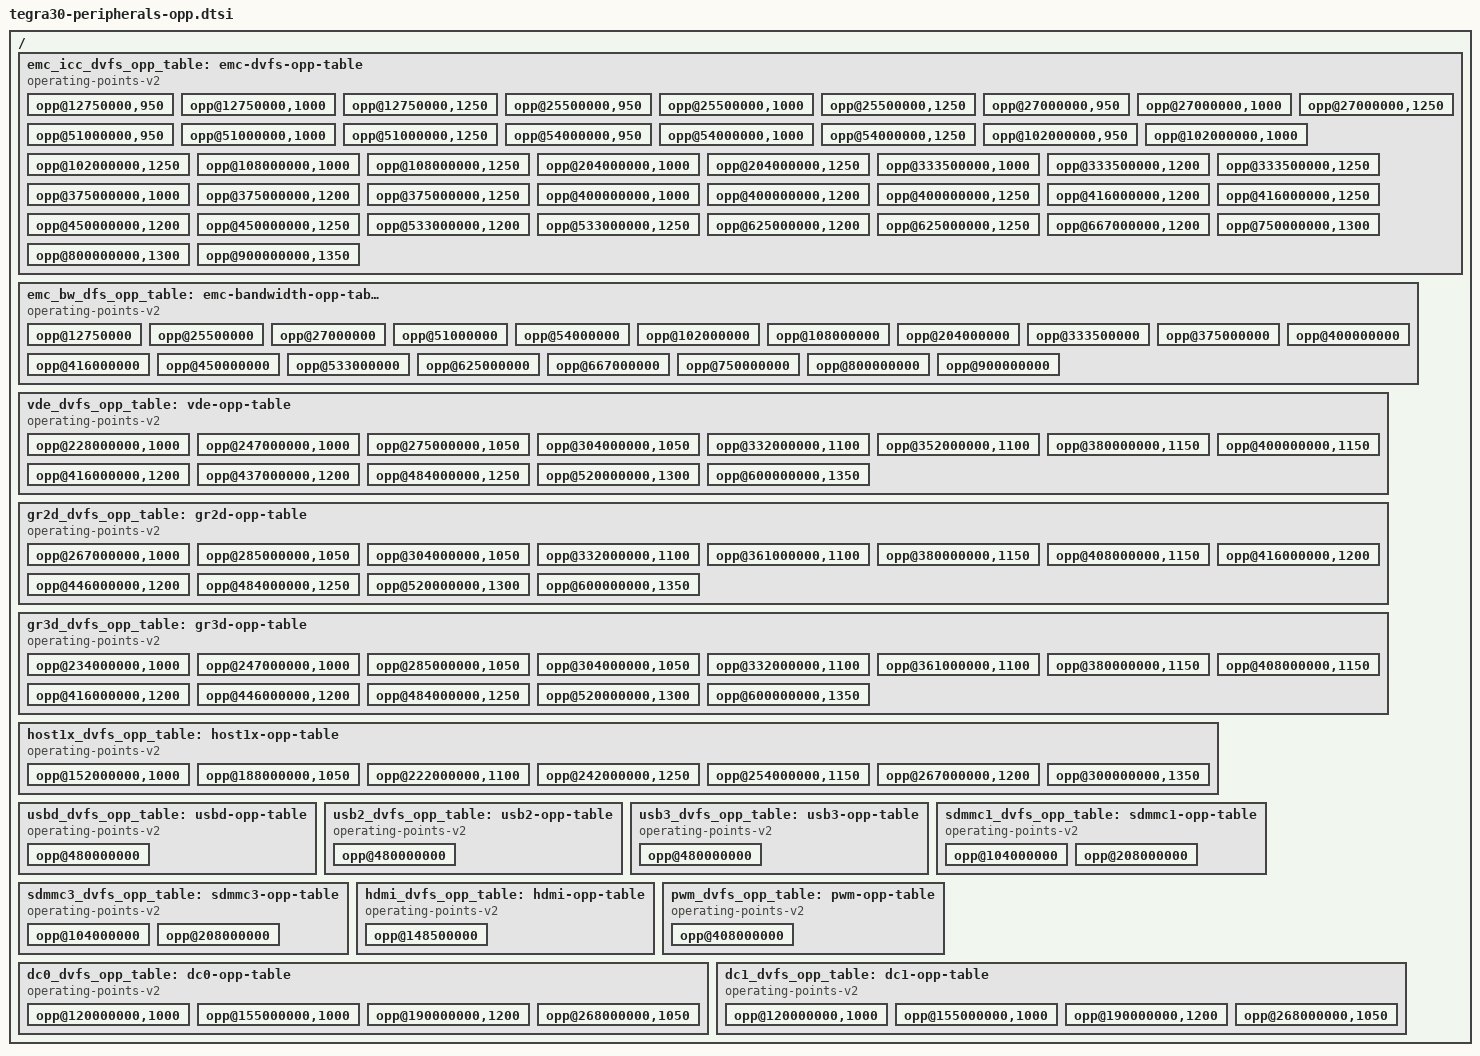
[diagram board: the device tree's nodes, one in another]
// SPDX-License-Identifier: GPL-2.0

/ {
	emc_icc_dvfs_opp_table: emc-dvfs-opp-table {
		compatible = "operating-points-v2";

		opp@12750000,950 {
			opp-microvolt = <950000 950000 1350000>;
			opp-hz = /bits/ 64 <12750000>;
			opp-supported-hw = <0x0006>;
		};

		opp@12750000,1000 {
			opp-microvolt = <1000000 1000000 1350000>;
			opp-hz = /bits/ 64 <12750000>;
			opp-supported-hw = <0x0001>;
		};

		opp@12750000,1250 {
			opp-microvolt = <1250000 1250000 1350000>;
			opp-hz = /bits/ 64 <12750000>;
			opp-supported-hw = <0x0008>;
		};

		opp@25500000,950 {
			opp-microvolt = <950000 950000 1350000>;
			opp-hz = /bits/ 64 <25500000>;
			opp-supported-hw = <0x0006>;
		};

		opp@25500000,1000 {
			opp-microvolt = <1000000 1000000 1350000>;
			opp-hz = /bits/ 64 <25500000>;
			opp-supported-hw = <0x0001>;
		};

		opp@25500000,1250 {
			opp-microvolt = <1250000 1250000 1350000>;
			opp-hz = /bits/ 64 <25500000>;
			opp-supported-hw = <0x0008>;
		};

		opp@27000000,950 {
			opp-microvolt = <950000 950000 1350000>;
			opp-hz = /bits/ 64 <27000000>;
			opp-supported-hw = <0x0006>;
		};

		opp@27000000,1000 {
			opp-microvolt = <1000000 1000000 1350000>;
			opp-hz = /bits/ 64 <27000000>;
			opp-supported-hw = <0x0001>;
		};

		opp@27000000,1250 {
			opp-microvolt = <1250000 1250000 1350000>;
			opp-hz = /bits/ 64 <27000000>;
			opp-supported-hw = <0x0008>;
		};

		opp@51000000,950 {
			opp-microvolt = <950000 950000 1350000>;
			opp-hz = /bits/ 64 <51000000>;
			opp-supported-hw = <0x0006>;
		};

		opp@51000000,1000 {
			opp-microvolt = <1000000 1000000 1350000>;
			opp-hz = /bits/ 64 <51000000>;
			opp-supported-hw = <0x0001>;
		};

		opp@51000000,1250 {
			opp-microvolt = <1250000 1250000 1350000>;
			opp-hz = /bits/ 64 <51000000>;
			opp-supported-hw = <0x0008>;
		};

		opp@54000000,950 {
			opp-microvolt = <950000 950000 1350000>;
			opp-hz = /bits/ 64 <54000000>;
			opp-supported-hw = <0x0006>;
		};

		opp@54000000,1000 {
			opp-microvolt = <1000000 1000000 1350000>;
			opp-hz = /bits/ 64 <54000000>;
			opp-supported-hw = <0x0001>;
		};

		opp@54000000,1250 {
			opp-microvolt = <1250000 1250000 1350000>;
			opp-hz = /bits/ 64 <54000000>;
			opp-supported-hw = <0x0008>;
		};

		opp@102000000,950 {
			opp-microvolt = <950000 950000 1350000>;
			opp-hz = /bits/ 64 <102000000>;
			opp-supported-hw = <0x0006>;
		};

		opp@102000000,1000 {
			opp-microvolt = <1000000 1000000 1350000>;
			opp-hz = /bits/ 64 <102000000>;
			opp-supported-hw = <0x0001>;
		};

		opp@102000000,1250 {
			opp-microvolt = <1250000 1250000 1350000>;
			opp-hz = /bits/ 64 <102000000>;
			opp-supported-hw = <0x0008>;
		};

		opp@108000000,1000 {
			opp-microvolt = <1000000 1000000 1350000>;
			opp-hz = /bits/ 64 <108000000>;
			opp-supported-hw = <0x0007>;
		};

		opp@108000000,1250 {
			opp-microvolt = <1250000 1250000 1350000>;
			opp-hz = /bits/ 64 <108000000>;
			opp-supported-hw = <0x0008>;
		};

		opp@204000000,1000 {
			opp-microvolt = <1000000 1000000 1350000>;
			opp-hz = /bits/ 64 <204000000>;
			opp-supported-hw = <0x0007>;
		};

		opp@204000000,1250 {
			opp-microvolt = <1250000 1250000 1350000>;
			opp-hz = /bits/ 64 <204000000>;
			opp-supported-hw = <0x0008>;
		};

		opp@333500000,1000 {
			opp-microvolt = <1000000 1000000 1350000>;
			opp-hz = /bits/ 64 <333500000>;
			opp-supported-hw = <0x0006>;
		};

		opp@333500000,1200 {
			opp-microvolt = <1200000 1200000 1350000>;
			opp-hz = /bits/ 64 <333500000>;
			opp-supported-hw = <0x0001>;
		};

		opp@333500000,1250 {
			opp-microvolt = <1250000 1250000 1350000>;
			opp-hz = /bits/ 64 <333500000>;
			opp-supported-hw = <0x0008>;
		};

		opp@375000000,1000 {
			opp-microvolt = <1000000 1000000 1350000>;
			opp-hz = /bits/ 64 <375000000>;
			opp-supported-hw = <0x0006>;
		};

		opp@375000000,1200 {
			opp-microvolt = <1200000 1200000 1350000>;
			opp-hz = /bits/ 64 <375000000>;
			opp-supported-hw = <0x0001>;
		};

		opp@375000000,1250 {
			opp-microvolt = <1250000 1250000 1350000>;
			opp-hz = /bits/ 64 <375000000>;
			opp-supported-hw = <0x0008>;
		};

		opp@400000000,1000 {
			opp-microvolt = <1000000 1000000 1350000>;
			opp-hz = /bits/ 64 <400000000>;
			opp-supported-hw = <0x0006>;
		};

		opp@400000000,1200 {
			opp-microvolt = <1200000 1200000 1350000>;
			opp-hz = /bits/ 64 <400000000>;
			opp-supported-hw = <0x0001>;
		};

		opp@400000000,1250 {
			opp-microvolt = <1250000 1250000 1350000>;
			opp-hz = /bits/ 64 <400000000>;
			opp-supported-hw = <0x0008>;
		};

		opp@416000000,1200 {
			opp-microvolt = <1200000 1200000 1350000>;
			opp-hz = /bits/ 64 <416000000>;
			opp-supported-hw = <0x0007>;
		};

		opp@416000000,1250 {
			opp-microvolt = <1250000 1250000 1350000>;
			opp-hz = /bits/ 64 <416000000>;
			opp-supported-hw = <0x0008>;
		};

		opp@450000000,1200 {
			opp-microvolt = <1200000 1200000 1350000>;
			opp-hz = /bits/ 64 <450000000>;
			opp-supported-hw = <0x0007>;
		};

		opp@450000000,1250 {
			opp-microvolt = <1250000 1250000 1350000>;
			opp-hz = /bits/ 64 <450000000>;
			opp-supported-hw = <0x0008>;
		};

		opp@533000000,1200 {
			opp-microvolt = <1200000 1200000 1350000>;
			opp-hz = /bits/ 64 <533000000>;
			opp-supported-hw = <0x0007>;
		};

		opp@533000000,1250 {
			opp-microvolt = <1250000 1250000 1350000>;
			opp-hz = /bits/ 64 <533000000>;
			opp-supported-hw = <0x0008>;
		};

		opp@625000000,1200 {
			opp-microvolt = <1200000 1200000 1350000>;
			opp-hz = /bits/ 64 <625000000>;
			opp-supported-hw = <0x0006>;
		};

		opp@625000000,1250 {
			opp-microvolt = <1250000 1250000 1350000>;
			opp-hz = /bits/ 64 <625000000>;
			opp-supported-hw = <0x0008>;
		};

		opp@667000000,1200 {
			opp-microvolt = <1200000 1200000 1350000>;
			opp-hz = /bits/ 64 <667000000>;
			opp-supported-hw = <0x0006>;
		};

		opp@750000000,1300 {
			opp-microvolt = <1300000 1300000 1350000>;
			opp-hz = /bits/ 64 <750000000>;
			opp-supported-hw = <0x0004>;
		};

		opp@800000000,1300 {
			opp-microvolt = <1300000 1300000 1350000>;
			opp-hz = /bits/ 64 <800000000>;
			opp-supported-hw = <0x0004>;
		};

		opp@900000000,1350 {
			opp-microvolt = <1350000 1350000 1350000>;
			opp-hz = /bits/ 64 <900000000>;
			opp-supported-hw = <0x0004>;
		};
	};

	emc_bw_dfs_opp_table: emc-bandwidth-opp-table {
		compatible = "operating-points-v2";

		opp@12750000 {
			opp-hz = /bits/ 64 <12750000>;
			opp-supported-hw = <0x000F>;
			opp-peak-kBps = <102000>;
		};

		opp@25500000 {
			opp-hz = /bits/ 64 <25500000>;
			opp-supported-hw = <0x000F>;
			opp-peak-kBps = <204000>;
		};

		opp@27000000 {
			opp-hz = /bits/ 64 <27000000>;
			opp-supported-hw = <0x000F>;
			opp-peak-kBps = <216000>;
		};

		opp@51000000 {
			opp-hz = /bits/ 64 <51000000>;
			opp-supported-hw = <0x000F>;
			opp-peak-kBps = <408000>;
		};

		opp@54000000 {
			opp-hz = /bits/ 64 <54000000>;
			opp-supported-hw = <0x000F>;
			opp-peak-kBps = <432000>;
		};

		opp@102000000 {
			opp-hz = /bits/ 64 <102000000>;
			opp-supported-hw = <0x000F>;
			opp-peak-kBps = <816000>;
		};

		opp@108000000 {
			opp-hz = /bits/ 64 <108000000>;
			opp-supported-hw = <0x000F>;
			opp-peak-kBps = <864000>;
		};

		opp@204000000 {
			opp-hz = /bits/ 64 <204000000>;
			opp-supported-hw = <0x000F>;
			opp-peak-kBps = <1632000>;
		};

		opp@333500000 {
			opp-hz = /bits/ 64 <333500000>;
			opp-supported-hw = <0x000F>;
			opp-peak-kBps = <2668000>;
		};

		opp@375000000 {
			opp-hz = /bits/ 64 <375000000>;
			opp-supported-hw = <0x000F>;
			opp-peak-kBps = <3000000>;
		};

		opp@400000000 {
			opp-hz = /bits/ 64 <400000000>;
			opp-supported-hw = <0x000F>;
			opp-peak-kBps = <3200000>;
		};

		opp@416000000 {
			opp-hz = /bits/ 64 <416000000>;
			opp-supported-hw = <0x000F>;
			opp-peak-kBps = <3328000>;
		};

		opp@450000000 {
			opp-hz = /bits/ 64 <450000000>;
			opp-supported-hw = <0x000F>;
			opp-peak-kBps = <3600000>;
		};

		opp@533000000 {
			opp-hz = /bits/ 64 <533000000>;
			opp-supported-hw = <0x000F>;
			opp-peak-kBps = <4264000>;
		};

		opp@625000000 {
			opp-hz = /bits/ 64 <625000000>;
			opp-supported-hw = <0x000E>;
			opp-peak-kBps = <5000000>;
		};

		opp@667000000 {
			opp-hz = /bits/ 64 <667000000>;
			opp-supported-hw = <0x0006>;
			opp-peak-kBps = <5336000>;
		};

		opp@750000000 {
			opp-hz = /bits/ 64 <750000000>;
			opp-supported-hw = <0x0004>;
			opp-peak-kBps = <6000000>;
		};

		opp@800000000 {
			opp-hz = /bits/ 64 <800000000>;
			opp-supported-hw = <0x0004>;
			opp-peak-kBps = <6400000>;
		};

		opp@900000000 {
			opp-hz = /bits/ 64 <900000000>;
			opp-supported-hw = <0x0004>;
			opp-peak-kBps = <7200000>;
		};
	};

	vde_dvfs_opp_table: vde-opp-table {
		compatible = "operating-points-v2";

		opp@228000000,1000 {
			opp-microvolt = <1000000 1000000 1350000>;
			opp-hz = /bits/ 64 <228000000>;
			opp-supported-hw = <0x0003>;
		};

		opp@247000000,1000 {
			opp-microvolt = <1000000 1000000 1350000>;
			opp-hz = /bits/ 64 <247000000>;
			opp-supported-hw = <0x0004>;
		};

		opp@275000000,1050 {
			opp-microvolt = <1050000 1050000 1350000>;
			opp-hz = /bits/ 64 <275000000>;
			opp-supported-hw = <0x0003>;
		};

		opp@304000000,1050 {
			opp-microvolt = <1050000 1050000 1350000>;
			opp-hz = /bits/ 64 <304000000>;
			opp-supported-hw = <0x0004>;
		};

		opp@332000000,1100 {
			opp-microvolt = <1100000 1100000 1350000>;
			opp-hz = /bits/ 64 <332000000>;
			opp-supported-hw = <0x0003>;
		};

		opp@352000000,1100 {
			opp-microvolt = <1100000 1100000 1350000>;
			opp-hz = /bits/ 64 <352000000>;
			opp-supported-hw = <0x0004>;
		};

		opp@380000000,1150 {
			opp-microvolt = <1150000 1150000 1350000>;
			opp-hz = /bits/ 64 <380000000>;
			opp-supported-hw = <0x0003>;
		};

		opp@400000000,1150 {
			opp-microvolt = <1150000 1150000 1350000>;
			opp-hz = /bits/ 64 <400000000>;
			opp-supported-hw = <0x0004>;
		};

		opp@416000000,1200 {
			opp-microvolt = <1200000 1200000 1350000>;
			opp-hz = /bits/ 64 <416000000>;
			opp-supported-hw = <0x0003>;
		};

		opp@437000000,1200 {
			opp-microvolt = <1200000 1200000 1350000>;
			opp-hz = /bits/ 64 <437000000>;
			opp-supported-hw = <0x0004>;
		};

		opp@484000000,1250 {
			opp-microvolt = <1250000 1250000 1350000>;
			opp-hz = /bits/ 64 <484000000>;
			opp-supported-hw = <0x000C>;
		};

		opp@520000000,1300 {
			opp-microvolt = <1300000 1300000 1350000>;
			opp-hz = /bits/ 64 <520000000>;
			opp-supported-hw = <0x0004>;
		};

		opp@600000000,1350 {
			opp-microvolt = <1350000 1350000 1350000>;
			opp-hz = /bits/ 64 <600000000>;
			opp-supported-hw = <0x0004>;
		};
	};

	gr2d_dvfs_opp_table: gr2d-opp-table {
		compatible = "operating-points-v2";

		opp@267000000,1000 {
			opp-microvolt = <1000000 1000000 1350000>;
			opp-hz = /bits/ 64 <267000000>;
			opp-supported-hw = <0x0007>;
		};

		opp@285000000,1050 {
			opp-microvolt = <1050000 1050000 1350000>;
			opp-hz = /bits/ 64 <285000000>;
			opp-supported-hw = <0x0003>;
		};

		opp@304000000,1050 {
			opp-microvolt = <1050000 1050000 1350000>;
			opp-hz = /bits/ 64 <304000000>;
			opp-supported-hw = <0x0004>;
		};

		opp@332000000,1100 {
			opp-microvolt = <1100000 1100000 1350000>;
			opp-hz = /bits/ 64 <332000000>;
			opp-supported-hw = <0x0003>;
		};

		opp@361000000,1100 {
			opp-microvolt = <1100000 1100000 1350000>;
			opp-hz = /bits/ 64 <361000000>;
			opp-supported-hw = <0x0004>;
		};

		opp@380000000,1150 {
			opp-microvolt = <1150000 1150000 1350000>;
			opp-hz = /bits/ 64 <380000000>;
			opp-supported-hw = <0x0003>;
		};

		opp@408000000,1150 {
			opp-microvolt = <1150000 1150000 1350000>;
			opp-hz = /bits/ 64 <408000000>;
			opp-supported-hw = <0x0004>;
		};

		opp@416000000,1200 {
			opp-microvolt = <1200000 1200000 1350000>;
			opp-hz = /bits/ 64 <416000000>;
			opp-supported-hw = <0x0003>;
		};

		opp@446000000,1200 {
			opp-microvolt = <1200000 1200000 1350000>;
			opp-hz = /bits/ 64 <446000000>;
			opp-supported-hw = <0x0004>;
		};

		opp@484000000,1250 {
			opp-microvolt = <1250000 1250000 1350000>;
			opp-hz = /bits/ 64 <484000000>;
			opp-supported-hw = <0x000C>;
		};

		opp@520000000,1300 {
			opp-microvolt = <1300000 1300000 1350000>;
			opp-hz = /bits/ 64 <520000000>;
			opp-supported-hw = <0x0004>;
		};

		opp@600000000,1350 {
			opp-microvolt = <1350000 1350000 1350000>;
			opp-hz = /bits/ 64 <600000000>;
			opp-supported-hw = <0x0004>;
		};
	};

	gr3d_dvfs_opp_table: gr3d-opp-table {
		compatible = "operating-points-v2";

		opp@234000000,1000 {
			opp-microvolt = <1000000 1000000 1350000>;
			opp-hz = /bits/ 64 <234000000>;
			opp-supported-hw = <0x0003>;
		};

		opp@247000000,1000 {
			opp-microvolt = <1000000 1000000 1350000>;
			opp-hz = /bits/ 64 <247000000>;
			opp-supported-hw = <0x0004>;
		};

		opp@285000000,1050 {
			opp-microvolt = <1050000 1050000 1350000>;
			opp-hz = /bits/ 64 <285000000>;
			opp-supported-hw = <0x0003>;
		};

		opp@304000000,1050 {
			opp-microvolt = <1050000 1050000 1350000>;
			opp-hz = /bits/ 64 <304000000>;
			opp-supported-hw = <0x0004>;
		};

		opp@332000000,1100 {
			opp-microvolt = <1100000 1100000 1350000>;
			opp-hz = /bits/ 64 <332000000>;
			opp-supported-hw = <0x0003>;
		};

		opp@361000000,1100 {
			opp-microvolt = <1100000 1100000 1350000>;
			opp-hz = /bits/ 64 <361000000>;
			opp-supported-hw = <0x0004>;
		};

		opp@380000000,1150 {
			opp-microvolt = <1150000 1150000 1350000>;
			opp-hz = /bits/ 64 <380000000>;
			opp-supported-hw = <0x0003>;
		};

		opp@408000000,1150 {
			opp-microvolt = <1150000 1150000 1350000>;
			opp-hz = /bits/ 64 <408000000>;
			opp-supported-hw = <0x0004>;
		};

		opp@416000000,1200 {
			opp-microvolt = <1200000 1200000 1350000>;
			opp-hz = /bits/ 64 <416000000>;
			opp-supported-hw = <0x0003>;
		};

		opp@446000000,1200 {
			opp-microvolt = <1200000 1200000 1350000>;
			opp-hz = /bits/ 64 <446000000>;
			opp-supported-hw = <0x0004>;
		};

		opp@484000000,1250 {
			opp-microvolt = <1250000 1250000 1350000>;
			opp-hz = /bits/ 64 <484000000>;
			opp-supported-hw = <0x000C>;
		};

		opp@520000000,1300 {
			opp-microvolt = <1300000 1300000 1350000>;
			opp-hz = /bits/ 64 <520000000>;
			opp-supported-hw = <0x0004>;
		};

		opp@600000000,1350 {
			opp-microvolt = <1350000 1350000 1350000>;
			opp-hz = /bits/ 64 <600000000>;
			opp-supported-hw = <0x0004>;
		};
	};

	host1x_dvfs_opp_table: host1x-opp-table {
		compatible = "operating-points-v2";

		opp@152000000,1000 {
			opp-microvolt = <1000000 1000000 1350000>;
			opp-hz = /bits/ 64 <152000000>;
			opp-supported-hw = <0x0007>;
		};

		opp@188000000,1050 {
			opp-microvolt = <1050000 1050000 1350000>;
			opp-hz = /bits/ 64 <188000000>;
			opp-supported-hw = <0x0007>;
		};

		opp@222000000,1100 {
			opp-microvolt = <1100000 1100000 1350000>;
			opp-hz = /bits/ 64 <222000000>;
			opp-supported-hw = <0x0007>;
		};

		opp@242000000,1250 {
			opp-microvolt = <1250000 1250000 1350000>;
			opp-hz = /bits/ 64 <242000000>;
			opp-supported-hw = <0x0008>;
		};

		opp@254000000,1150 {
			opp-microvolt = <1150000 1150000 1350000>;
			opp-hz = /bits/ 64 <254000000>;
			opp-supported-hw = <0x0007>;
		};

		opp@267000000,1200 {
			opp-microvolt = <1200000 1200000 1350000>;
			opp-hz = /bits/ 64 <267000000>;
			opp-supported-hw = <0x0007>;
		};

		opp@300000000,1350 {
			opp-microvolt = <1350000 1350000 1350000>;
			opp-hz = /bits/ 64 <300000000>;
			opp-supported-hw = <0x0004>;
		};
	};

	usbd_dvfs_opp_table: usbd-opp-table {
		compatible = "operating-points-v2";

		opp@480000000 {
			opp-microvolt = <1000000 1000000 1350000>;
			opp-hz = /bits/ 64 <480000000>;
		};
	};

	usb2_dvfs_opp_table: usb2-opp-table {
		compatible = "operating-points-v2";

		opp@480000000 {
			opp-microvolt = <1000000 1000000 1350000>;
			opp-hz = /bits/ 64 <480000000>;
		};
	};

	usb3_dvfs_opp_table: usb3-opp-table {
		compatible = "operating-points-v2";

		opp@480000000 {
			opp-microvolt = <1000000 1000000 1350000>;
			opp-hz = /bits/ 64 <480000000>;
		};
	};

	sdmmc1_dvfs_opp_table: sdmmc1-opp-table {
		compatible = "operating-points-v2";

		opp@104000000 {
			opp-microvolt = <950000 950000 1350000>;
			opp-hz = /bits/ 64 <104000000>;
		};

		opp@208000000 {
			opp-microvolt = <1200000 1200000 1350000>;
			opp-hz = /bits/ 64 <208000000>;
		};
	};

	sdmmc3_dvfs_opp_table: sdmmc3-opp-table {
		compatible = "operating-points-v2";

		opp@104000000 {
			opp-microvolt = <950000 950000 1350000>;
			opp-hz = /bits/ 64 <104000000>;
		};

		opp@208000000 {
			opp-microvolt = <1200000 1200000 1350000>;
			opp-hz = /bits/ 64 <208000000>;
		};
	};

	hdmi_dvfs_opp_table: hdmi-opp-table {
		compatible = "operating-points-v2";

		opp@148500000 {
			opp-microvolt = <1000000 1000000 1350000>;
			opp-hz = /bits/ 64 <148500000>;
		};
	};

	pwm_dvfs_opp_table: pwm-opp-table {
		compatible = "operating-points-v2";

		opp@408000000 {
			opp-microvolt = <1000000 1000000 1350000>;
			opp-hz = /bits/ 64 <408000000>;
		};
	};

	dc0_dvfs_opp_table: dc0-opp-table {
		compatible = "operating-points-v2";

		opp@120000000,1000 {
			opp-microvolt = <1000000 1000000 1350000>;
			opp-hz = /bits/ 64 <120000000>;
			opp-supported-hw = <0x0009>;
		};

		opp@155000000,1000 {
			opp-microvolt = <1000000 1000000 1350000>;
			opp-hz = /bits/ 64 <155000000>;
			opp-supported-hw = <0x0006>;
		};

		opp@190000000,1200 {
			opp-microvolt = <1200000 1200000 1350000>;
			opp-hz = /bits/ 64 <190000000>;
			opp-supported-hw = <0x0009>;
		};

		opp@268000000,1050 {
			opp-microvolt = <1050000 1050000 1350000>;
			opp-hz = /bits/ 64 <268000000>;
			opp-supported-hw = <0x0006>;
		};
	};

	dc1_dvfs_opp_table: dc1-opp-table {
		compatible = "operating-points-v2";

		opp@120000000,1000 {
			opp-microvolt = <1000000 1000000 1350000>;
			opp-hz = /bits/ 64 <120000000>;
			opp-supported-hw = <0x0009>;
		};

		opp@155000000,1000 {
			opp-microvolt = <1000000 1000000 1350000>;
			opp-hz = /bits/ 64 <155000000>;
			opp-supported-hw = <0x0006>;
		};

		opp@190000000,1200 {
			opp-microvolt = <1200000 1200000 1350000>;
			opp-hz = /bits/ 64 <190000000>;
			opp-supported-hw = <0x0009>;
		};

		opp@268000000,1050 {
			opp-microvolt = <1050000 1050000 1350000>;
			opp-hz = /bits/ 64 <268000000>;
			opp-supported-hw = <0x0006>;
		};
	};
};
